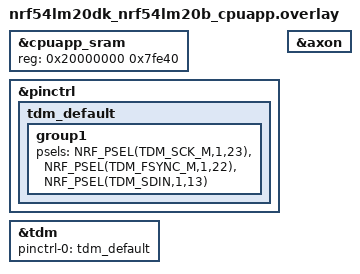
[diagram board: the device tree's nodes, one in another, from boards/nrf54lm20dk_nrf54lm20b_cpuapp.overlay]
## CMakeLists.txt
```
#
# Copyright (c) 2018 Nordic Semiconductor
#
# SPDX-License-Identifier: LicenseRef-Nordic-5-Clause
#
cmake_minimum_required(VERSION 3.20.0)

find_package(Zephyr REQUIRED HINTS $ENV{ZEPHYR_BASE})
project(NONE)

# NORDIC SDK APP START
target_sources(app PRIVATE
  src/main.c
  src/beamform.c
  src/bluetooth.c
  src/vad.c
  src/wakeword.c
  src/nrf_edgeai_generated/nrf_edgeai_user_model.c
)

# NORDIC SDK APP END
```

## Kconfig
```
#
# Copyright (c) 2018 Nordic Semiconductor
#
# SPDX-License-Identifier: LicenseRef-Nordic-5-Clause
#

source "Kconfig.zephyr"

menu "Wakeword and Keyword Spotting application"

config WW_PROBABILITY_THRESHOLD
	int "Wakeword probability threshold"
	range 0 1000
	default 700
	help
	   Probability threshold for wakeword detection model. The value is expressed in units of
	   1/1000.

config WW_HISTORY_SIZE
	int "Size of wakeword predictions history"
	range 1 32
	default 6
	help
	  Size of history of previous results from wakeword detection model.

config WW_COUNT_THRESHOLD
	int "Threshold for wakeword detection from predictions history"
	range 1 WW_HISTORY_SIZE
	default 4
	help
	  Number of predictions above threshold in predictions history required to confirm wakeword
	  detection.

endmenu

menu "Beamformer VAD / endpointing"

config APP_VAD_SAMPLE_RATE_HZ
	int "PCM sample rate handed to the VAD (Hz)"
	default 16000
	help
	  Must match the beamformer capture rate. Frame durations, and therefore
	  the silence and onset frame counts, are derived from this.

config APP_VAD_NOISE_INIT_RMS
	int "Initial noise-floor RMS estimate"
	default 25
	help
	  Seed value for the adaptive noise floor. Capture is always on, so the
	  floor is normally well converged before the Start button is pressed.
	  Matches the value proven in 10_beam_wakeword on the same int16 scale.

config APP_VAD_ONSET_RATIO_X8
	int "Speech-onset threshold as a multiple of the noise floor, in eighths"
	default 48
	help
	  threshold_on = noise_floor * this / 8. Default 48 is 6.0x. Measured
	  speech peaks on this hardware sit 13-19x above the room floor, so 6x
	  lands well inside speech while staying clear of the noise.

config APP_VAD_OFF_RATIO_X8
	int "Speech-continuation threshold as a multiple of the noise floor, in eighths"
	default 28
	help
	  threshold_off = noise_floor * this / 8. Default 20 is 2.5x. Must be
	  below APP_VAD_ONSET_RATIO_X8; the gap between them is the hysteresis
	  that carries the recording through pauses between words.

config APP_VAD_MARGIN_ON
	int "Absolute floor under the onset threshold (RMS counts)"
	default 40
	help
	  threshold_on never drops below noise_floor + this, so a near-silent
	  room cannot collapse the onset gate onto the noise.

config APP_VAD_MARGIN_OFF
	int "Absolute floor under the continuation threshold (RMS counts)"
	default 20
	help
	  threshold_off never drops below noise_floor + this. Must be less than
	  APP_VAD_MARGIN_ON.

config APP_VAD_ONSET_MS
	int "Sustained loud audio required to declare speech onset (ms)"
	default 32
	help
	  Debounces clicks, knocks and door slams. Rounded up to whole audio
	  frames, so on a 16 ms frame this is two frames.

config APP_VAD_SILENCE_END_MS
	int "Continuous silence that ends an utterance (ms)"
	default 600
	help
	  The endpoint pause. Ordinary gaps between words are shorter than this
	  and do not stop the recording. 500-1000 is the useful range: shorter
	  clips people who pause mid-sentence, longer adds latency.

config APP_VAD_MIN_SPEECH_MS
	int "Minimum utterance length before an endpoint may fire (ms)"
	default 300
	help
	  Guards against a single spurious onset frame immediately endpointing
	  and producing a near-empty recording.

config APP_VAD_NOISE_ALPHA_SHIFT
	int "Noise-floor adaptation shift"
	default 5
	help
	  noise += (rms - noise) >> this. Larger adapts more slowly.
	  5 gives a 1/32 step. The floor only adapts outside speech.

config APP_PREROLL_MS
	int "Audio kept from before the trigger (ms)"
	default 320
	help
	  A ring buffer of recent frames is always running, and its contents are
	  sent ahead of the live stream when recording starts. This covers the
	  wake-word model's confirmation delay, so the opening of an utterance
	  is not lost.

config APP_VAD_DEBUG
	bool "Verbose per-frame VAD telemetry"
	default y
	help
	  Logs rate-limited frame geometry, RMS, noise floor, both thresholds
	  and the silence/speech frame counters. Enough to see whether audio is
	  still arriving after you stop talking and whether the silence run is
	  reaching its target. Turn off for quiet production logs.

endmenu

menu "Nordic UART BLE GATT service sample"

config BT_NUS_THREAD_STACK_SIZE
	int "Thread stack size"
	default 1024
	help
	  Stack size used in each of the two threads

config BT_NUS_UART_BUFFER_SIZE
	int "UART payload buffer element size"
	default 40
	help
	  Size of the payload buffer in each RX and TX FIFO element

config BT_NUS_SECURITY_ENABLED
	bool "Security"
	default y
	select BT_SMP
	help
	  Enable Bluetooth LE security for the UART service

config BT_NUS_UART_RX_WAIT_TIME
	int "Timeout for UART RX complete event"
	default 50000
	help
	  Wait for RX complete event time in microseconds

config SETTINGS
	default y

config ZMS
	default y if (SOC_FLASH_NRF_RRAM || SOC_FLASH_NRF_MRAM)

config NVS
	default y if !(SOC_FLASH_NRF_RRAM || SOC_FLASH_NRF_MRAM)

endmenu
```

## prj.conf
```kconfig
# i2s
CONFIG_I2S=y

# serial console logs
CONFIG_LOG=y
CONFIG_LOG_DEFAULT_LEVEL=3
CONFIG_SERIAL=y
CONFIG_CONSOLE=y
CONFIG_UART_CONSOLE=y

# thread stakcs
CONFIG_MAIN_STACK_SIZE=4096
CONFIG_SYSTEM_WORKQUEUE_STACK_SIZE=2048
CONFIG_HEAP_MEM_POOL_SIZE=0

# buttons
CONFIG_GPIO=y
CONFIG_DK_LIBRARY=y

# bluetooth
CONFIG_BT=y
CONFIG_BT_PERIPHERAL=y
CONFIG_BT_NUS=y
CONFIG_BT_DEVICE_NAME="Beamformer"
CONFIG_BT_MAX_CONN=1
CONFIG_BT_L2CAP_TX_MTU=247
CONFIG_BT_BUF_ACL_TX_SIZE=251
CONFIG_BT_BUF_ACL_TX_COUNT=4
CONFIG_BT_BUF_ACL_RX_SIZE=251

# nRF Edge AI wakeword
CONFIG_NRF_EDGEAI=y
CONFIG_NRF_AXON=y
CONFIG_NEWLIB_LIBC=y
CONFIG_FPU=y
CONFIG_NRF_AXON_INTERLAYER_BUFFER_SIZE=7000
CONFIG_NRF_AXON_PSUM_BUFFER_SIZE=0

CONFIG_WW_PROBABILITY_THRESHOLD=700
CONFIG_WW_HISTORY_SIZE=6
CONFIG_WW_COUNT_THRESHOLD=4

CONFIG_NRF_SYS_EVENT=y
# VAD endpoint tuning
CONFIG_APP_VAD_SILENCE_END_MS=600
```

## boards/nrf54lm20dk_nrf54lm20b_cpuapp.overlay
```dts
/*
 * Copyright (c) 2026 Nordic Semiconductor ASA
 *
 * SPDX-License-Identifier: LicenseRef-Nordic-5-Clause
 */

 #include <dt-bindings/pinctrl/nrf-pinctrl.h>

&cpuapp_sram {
	reg = <0x20000000 0x7fe40>;
	ranges = <0x0 0x20000000 0x7fe40>;
};

&pinctrl {
	tdm_default: tdm_default {
		group1 {
			psels = <NRF_PSEL(TDM_SCK_M,1,23)>,
				<NRF_PSEL(TDM_FSYNC_M,1,22)>,
				<NRF_PSEL(TDM_SDIN,1,13)>;
		};
	};
};

&tdm {
	status = "okay";
	pinctrl-0 = <&tdm_default>;
	pinctrl-names = "default";
};

&axon {
	status = "okay";
};
```

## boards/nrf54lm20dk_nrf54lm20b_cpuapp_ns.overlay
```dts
/*
 * Copyright (c) 2026 N›ordic Semiconductor ASA
 *
 * SPDX-License-Identifier: LicenseRef-Nordic-5-Clause
 */

 #include <dt-bindings/pinctrl/nrf-pinctrl.h>

&cpuapp_sram {
	reg = <0x20000000 0x7fe40>;
	ranges = <0x0 0x20000000 0x7fe40>;
};

&pinctrl {
	tdm_default: tdm_default {
		group1 {
			psels = <NRF_PSEL(TDM_SCK_M,1,23)>,
				<NRF_PSEL(TDM_FSYNC_M,1,22)>,
				<NRF_PSEL(TDM_SDIN,1,13)>;
		};
	};
};

&tdm {
	status = "okay";
	pinctrl-0 = <&tdm_default>;
	pinctrl-names = "default";
};

&axon {
	status = "okay";
};
```

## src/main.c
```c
#include <errno.h>
#include <zephyr/kernel.h>
#include <zephyr/logging/log.h>
#include <zephyr/sys/atomic.h>
#include <zephyr/sys/util.h>
#include <string.h>
#include <dk_buttons_and_leds.h>

#include "beamform.h"
#include "bluetooth.h"
#include "vad.h"
#include "wakeword.h"

LOG_MODULE_REGISTER(main, LOG_LEVEL_INF);

#define MAX_STREAM_MS 30000U // never stopped speaking
#define NO_SPEECH_TIMEOUT_MS 10000U // never starts speaking
#define VAD_DEBUG_FRAMES_LISTENING 16U
#define VAD_DEBUG_FRAMES_IDLE 128U

enum audio_state {
	STATE_IDLE = BIT(0),
	STATE_LISTENING = BIT(1),
	STATE_FINALIZE = BIT(2),
	STATE_PROCESSING = BIT(3),
	STATE_RESPONDING = BIT(4),
};

enum stop_reason {
	STOP_NONE = 0,
	STOP_VAD_ENDPOINT,
	STOP_BUTTON,
	STOP_MAX_DURATION,
	STOP_NO_SPEECH,
};

enum start_reason {
	START_BUTTON = 0,
	START_WAKEWORD,
};

static const char *const start_reason_name[] = {
	[START_BUTTON] = "BTN1",
	[START_WAKEWORD] = "wake word",
};

static const char *const stop_reason_name[] = {
	[STOP_NONE] = "none",
	[STOP_VAD_ENDPOINT] = "VAD_ENDPOINT (automatic)",
	[STOP_BUTTON] = "BTN2 (manual failsafe)",
	[STOP_MAX_DURATION] = "max duration",
	[STOP_NO_SPEECH] = "no speech detected",
};

static atomic_t audio_state = ATOMIC_INIT(STATE_IDLE);
static atomic_t capture_enabled = ATOMIC_INIT(0);
static atomic_t last_stop_reason = ATOMIC_INIT(STOP_NONE);

/* Written by the capture thread, read by the main loop. */
static atomic_t speech_started = ATOMIC_INIT(0);
static atomic_t wakeword_ready = ATOMIC_INIT(0);
static atomic_t last_start_reason = ATOMIC_INIT(START_BUTTON);

static int64_t listening_start_ms;
static int64_t speech_start_ms;

/*
 * Preroll ring. Every frame captured while idle is kept here, and the whole
 * ring is flushed ahead of the live stream when a session opens. That covers
 * the wake-word model's confirmation delay, which would otherwise swallow the
 * first syllables of the command. Only the capture thread touches it: writes
 * happen while idle, and the flush is done by the capture thread on its first
 * recording frame rather than by whichever thread pressed the button.
 */
#define PREROLL_FRAMES ((CONFIG_APP_PREROLL_MS * 16000U) / (256U * 1000U))

#if PREROLL_FRAMES > 0
static int16_t preroll[PREROLL_FRAMES][256];
static uint32_t preroll_head;
static uint32_t preroll_used;
#endif
static atomic_t preroll_pending = ATOMIC_INIT(0);

static void preroll_store(const int16_t *samples, size_t count)
{
#if PREROLL_FRAMES > 0
	if (count != 256U) {
		return;
	}

	memcpy(preroll[preroll_head], samples, count * sizeof(int16_t));
	preroll_head = (preroll_head + 1U) % PREROLL_FRAMES;
	if (preroll_used < PREROLL_FRAMES) {
		preroll_used++;
	}
#else
	ARG_UNUSED(samples);
	ARG_UNUSED(count);
#endif
}

static void preroll_flush(void)
{
#if PREROLL_FRAMES > 0
	uint32_t start = (preroll_head + PREROLL_FRAMES - preroll_used) % PREROLL_FRAMES;
	uint32_t sent = 0U;

	for (uint32_t i = 0; i < preroll_used; i++) {
		uint32_t idx = (start + i) % PREROLL_FRAMES;

		if (bluetooth_enqueue_audio(preroll[idx], 256U) == 0) {
			sent++;
		}
	}

	LOG_INF("Preroll: sent %u of %u frames (%u ms)", sent, preroll_used,
		sent * 256U * 1000U / 16000U);
	preroll_used = 0U;
#endif
}

static const struct vad_config vad_config = {
	.sample_rate_hz = CONFIG_APP_VAD_SAMPLE_RATE_HZ,
	.noise_init_rms = CONFIG_APP_VAD_NOISE_INIT_RMS,
	.onset_ratio_x8 = CONFIG_APP_VAD_ONSET_RATIO_X8,
	.off_ratio_x8 = CONFIG_APP_VAD_OFF_RATIO_X8,
	.margin_on = CONFIG_APP_VAD_MARGIN_ON,
	.margin_off = CONFIG_APP_VAD_MARGIN_OFF,
	.onset_ms = CONFIG_APP_VAD_ONSET_MS,
	.silence_end_ms = CONFIG_APP_VAD_SILENCE_END_MS,
	.min_speech_ms = CONFIG_APP_VAD_MIN_SPEECH_MS,
	.noise_alpha_shift = CONFIG_APP_VAD_NOISE_ALPHA_SHIFT,
};

static void log_vad_telemetry(const char *tag, bool listening)
{
	struct vad_debug d;

	vad_get_debug(&d);

	LOG_INF("VAD[%s] frame=%u smp/%u B (%u ms @%u Hz, 1 ch) rms=%u noise=%u "
		"on=%u off=%u -> %s | speech_active=%d onset=%u/%u silence=%u/%u "
		"speech=%u/%u latched=%d listening=%d",
		tag, d.frame_samples, d.frame_bytes, d.frame_ms, d.sample_rate_hz,
		d.rms, d.noise_rms, d.threshold_on, d.threshold_off,
		d.frame_is_speech ? "SPEECH" : "silence",
		d.speech_active ? 1 : 0, d.onset_frames, d.onset_frames_req,
		d.silence_frames, d.silence_end_frames,
		d.speech_frames, d.min_speech_frames, d.endpoint_latched ? 1 : 0,
		listening ? 1 : 0);
}

static void enter_state(enum audio_state next_state);

static bool request_finalize(enum stop_reason reason)
{
	if (!atomic_cas(&audio_state, STATE_LISTENING, STATE_FINALIZE)) {
		return false;
	}

	atomic_clear(&capture_enabled);
	atomic_set(&last_stop_reason, reason);

	LOG_INF("Recording stop: %s (after %lld ms)", stop_reason_name[reason],
		k_uptime_get() - listening_start_ms);
	LOG_INF("STATE_FINALIZE: capture disabled, draining BLE TX queue");

	return true;
}

static bool request_listen(enum start_reason reason)
{
	if (!atomic_cas(&audio_state, STATE_IDLE, STATE_LISTENING)) {
		return false;
	}

	atomic_set(&last_start_reason, reason);
	enter_state(STATE_LISTENING);

	return true;
}

static void enter_state(enum audio_state next_state)
{
	atomic_set(&audio_state, next_state);

	switch (next_state) {
	case STATE_IDLE:
		atomic_clear(&capture_enabled);
		ww_reset();
		LOG_INF("STATE_IDLE: say the wake word or press BTN1");
		break;

	case STATE_LISTENING:
		vad_reset_endpoint();
		ww_reset();
		bluetooth_tx_reset_stats();
		atomic_set(&preroll_pending, 1);
		atomic_clear(&speech_started);
		atomic_set(&last_stop_reason, STOP_NONE);
		listening_start_ms = k_uptime_get();
		speech_start_ms = 0;
		atomic_set(&capture_enabled, 1);
		LOG_INF("STATE_LISTENING: started by %s, waiting for speech, "
			"streaming enabled",
			start_reason_name[atomic_get(&last_start_reason)]);
		break;

	case STATE_FINALIZE:
		atomic_clear(&capture_enabled);
		LOG_INF("STATE_FINALIZE: capture disabled, draining BLE TX queue");
		break;

	case STATE_PROCESSING:
		atomic_clear(&capture_enabled);
		LOG_INF("STATE_PROCESSING");
		break;

	case STATE_RESPONDING:
		atomic_clear(&capture_enabled);
		LOG_INF("STATE_RESPONDING");
		break;

	default:
		LOG_ERR("Invalid state: 0x%x", next_state);
		atomic_set(&audio_state, STATE_IDLE);
		atomic_clear(&capture_enabled);
		break;
	}
}

static void on_beamformed_chunk(const int16_t *samples, size_t count)
{
	static uint32_t frames_since_log;
	enum audio_state current;
	enum vad_event event;
	bool listening;
	int err;

	current = (enum audio_state)atomic_get(&audio_state);
	listening = (current == STATE_LISTENING) && atomic_get(&capture_enabled);

	event = vad_process(samples, count, listening);

	if (!listening && current == STATE_IDLE && atomic_get(&wakeword_ready)) {
		bool ww_detected = false;

		err = ww_process(samples, (uint16_t)count, &ww_detected);
		if (err && err != -EBUSY) {
			LOG_WRN("Wakeword inference failed: %d", err);
		} else if (ww_detected) {
			LOG_INF("Wake word detected");
			request_listen(START_WAKEWORD);
			return;
		}
	}

	if (IS_ENABLED(CONFIG_APP_VAD_DEBUG)) {
		uint32_t period = listening ? VAD_DEBUG_FRAMES_LISTENING
					    : VAD_DEBUG_FRAMES_IDLE;

		if (++frames_since_log >= period) {
			frames_since_log = 0U;
			log_vad_telemetry(listening ? "rec" : "idle", listening);
		}
	}

	if (!listening) {
		preroll_store(samples, count);
		return;
	}

	if (atomic_cas(&preroll_pending, 1, 0)) {
		preroll_flush();
	}

	switch (event) {
	case VAD_SPEECH_STARTED:
		atomic_set(&speech_started, 1);
		speech_start_ms = k_uptime_get();
		LOG_INF("Speech onset detected (%lld ms after start)",
			speech_start_ms - listening_start_ms);
		if (IS_ENABLED(CONFIG_APP_VAD_DEBUG)) {
			log_vad_telemetry("onset", true);
		}
		break;

	case VAD_ENDPOINT:
		LOG_INF("VAD endpoint: %u ms of continuous silence after speech",
			CONFIG_APP_VAD_SILENCE_END_MS);
		if (IS_ENABLED(CONFIG_APP_VAD_DEBUG)) {
			log_vad_telemetry("endpoint", true);
		}
		
		(void)bluetooth_enqueue_audio(samples, count);
		request_finalize(STOP_VAD_ENDPOINT);
		return;

	case VAD_NO_EVENT:
	default:
		break;
	}

	err = bluetooth_enqueue_audio(samples, count);
	if (err && err != -ENOTCONN) {
		LOG_WRN("BLE TX queue rejected audio chunk: %d", err);
	}
}


// Button handler. BTN1 starts a session, BTN2 is the manual failsafe stop.
static void button_changed(uint32_t state, uint32_t changed)
{
	uint32_t pressed = state & changed;
	enum audio_state current = (enum audio_state)atomic_get(&audio_state);

	if (pressed & DK_BTN1_MSK) {
		if (request_listen(START_BUTTON)) {
			LOG_INF("BTN1 start requested");
		} else {
			LOG_WRN("BTN1 ignored: session already active (state 0x%x)",
				current);
		}
		return;
	}

	if (pressed & DK_BTN2_MSK) {
		if (!request_finalize(STOP_BUTTON)) {
			LOG_WRN("BTN2 ignored: not recording (state 0x%x)", current);
		}
	}
}

static void finalize_processing(void)
{
	enum audio_state current = (enum audio_state)atomic_get(&audio_state);
	uint32_t dropped;

	if (current == STATE_LISTENING) {
		int64_t elapsed = k_uptime_get() - listening_start_ms;

		if (elapsed >= MAX_STREAM_MS) {
			LOG_WRN("Maximum stream duration reached");
			request_finalize(STOP_MAX_DURATION);
		} else if (!atomic_get(&speech_started) &&
			   elapsed >= NO_SPEECH_TIMEOUT_MS) {
			LOG_WRN("No speech within %u ms", NO_SPEECH_TIMEOUT_MS);
			request_finalize(STOP_NO_SPEECH);
		}
		return;
	}

	if (current != STATE_FINALIZE || !bluetooth_tx_drained()) {
		return;
	}

	dropped = bluetooth_tx_dropped_chunks();
	if (dropped) {
		LOG_WRN("Finalization: %u audio chunks were dropped; "
			"the received recording has gaps", dropped);
	}

	LOG_INF("Finalization complete: reason=%s, %lld ms captured, "
		"speech_detected=%d",
		stop_reason_name[atomic_get(&last_stop_reason)],
		k_uptime_get() - listening_start_ms,
		atomic_get(&speech_started) ? 1 : 0);

	// post recording
	enter_state(STATE_PROCESSING);
	enter_state(STATE_IDLE);
}

int main(void)
{
	int err = dk_leds_init();

	if (err) {
		return err;
	}

	err = dk_buttons_init(button_changed);
	if (err) {
		return err;
	}

	err = vad_init(&vad_config);
	if (err) {
		LOG_ERR("VAD initialization failed: %d", err);
		return err;
	}

	err = ww_init();
	if (err) {
		LOG_ERR("Wakeword initialization failed: %d", err);
		return err;
	}
	atomic_set(&wakeword_ready, 1);

	err = bluetooth_init();
	if (err) {
		LOG_ERR("Bluetooth initialization failed: %d", err);
		return err;
	}

	err = beamform_init(on_beamformed_chunk);
	if (err) {
		LOG_ERR("Beamformer initialization failed: %d", err);
		return err;
	}

	err = beamform_start();
	if (err) {
		LOG_ERR("Always-on beamforming failed to start: %d", err);
		return err;
	}

	LOG_INF("Beamforming + wake word + adaptive VAD active");
	LOG_INF("VAD: %u Hz, endpoint after %u ms silence, min utterance %u ms",
		(uint32_t)CONFIG_APP_VAD_SAMPLE_RATE_HZ,
		(uint32_t)CONFIG_APP_VAD_SILENCE_END_MS,
		(uint32_t)CONFIG_APP_VAD_MIN_SPEECH_MS);
	LOG_INF("VAD thresholds: on=%u/8x off=%u/8x of noise floor "
		"(min +%u / +%u), noise init=%u, preroll %u frames",
		(uint32_t)CONFIG_APP_VAD_ONSET_RATIO_X8,
		(uint32_t)CONFIG_APP_VAD_OFF_RATIO_X8,
		(uint32_t)CONFIG_APP_VAD_MARGIN_ON,
		(uint32_t)CONFIG_APP_VAD_MARGIN_OFF,
		(uint32_t)CONFIG_APP_VAD_NOISE_INIT_RMS,
		(uint32_t)PREROLL_FRAMES);
	LOG_INF("Wakeword: prob>%u/1000, %u of last %u windows",
		(uint32_t)CONFIG_WW_PROBABILITY_THRESHOLD,
		(uint32_t)CONFIG_WW_COUNT_THRESHOLD,
		(uint32_t)CONFIG_WW_HISTORY_SIZE);
	LOG_INF("Wake word or BTN1: start recording   BTN2: manual failsafe stop");

	enter_state(STATE_IDLE);

	for (;;) {
		finalize_processing();
		k_sleep(K_MSEC(10));
	}
}
```

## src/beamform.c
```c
#include <errno.h>
#include <stdint.h>

#include <zephyr/device.h>
#include <zephyr/devicetree.h>
#include <zephyr/drivers/i2s.h>
#include <zephyr/kernel.h>
#include <zephyr/logging/log.h>
#include <zephyr/sys/atomic.h>
#include <zephyr/sys/util.h>

#include "beamform.h"

LOG_MODULE_REGISTER(beamform, LOG_LEVEL_INF);

#define SAMPLE_RATE       16000
#define SAMPLE_BIT_WIDTH  32
#define CHANNELS          2

#define BLOCK_PAIRS       256
#define BLOCK_BYTES       (BLOCK_PAIRS * CHANNELS * sizeof(int32_t))
#define BLOCK_COUNT       4
#define CAPTURE_GAIN_SHIFT 0

#define TDM_NODE DT_NODELABEL(tdm)

#if !DT_NODE_EXISTS(TDM_NODE)
#error "TDM node does not exist in the final devicetree"
#endif

#if !DT_NODE_HAS_STATUS(TDM_NODE, okay)
#error "TDM node is not enabled in the final devicetree"
#endif

K_MEM_SLAB_DEFINE_IN_SECT_STATIC(rx_slab, __nocache, BLOCK_BYTES, BLOCK_COUNT, 4);
K_THREAD_STACK_DEFINE(capture_stack, 4096);

static const struct device *const i2s = DEVICE_DT_GET(TDM_NODE);

static const struct i2s_config i2s_cfg = {
	.word_size = SAMPLE_BIT_WIDTH,
	.channels = CHANNELS,
	.format = I2S_FMT_DATA_FORMAT_I2S,
	/* The nRF TDM drives both clocks; the INMP441 is always a clock slave. */
	.options = I2S_OPT_BIT_CLK_MASTER | I2S_OPT_FRAME_CLK_MASTER,
	.frame_clk_freq = SAMPLE_RATE,
	.mem_slab = &rx_slab,
	.block_size = BLOCK_BYTES,
	.timeout = 2000,
};

static struct k_thread capture_thread_data;
static atomic_t beamforming_active = ATOMIC_INIT(0);
static void (*chunk_ready)(const int16_t *samples, size_t count);

/* Sign-preserving unpack of the 24-bit payload from its 32-bit I2S slot. */
static inline int32_t extract_sample_24(int32_t raw)
{
	return raw >> 8;
}

static inline int16_t saturate_int16(int32_t x)
{
	if (x > INT16_MAX) {
		return INT16_MAX;
	}
	if (x < INT16_MIN) {
		return INT16_MIN;
	}
	return (int16_t)x;
}

static void capture(void *a, void *b, void *c)
{
	ARG_UNUSED(a);
	ARG_UNUSED(b);
	ARG_UNUSED(c);

	int err = i2s_trigger(i2s, I2S_DIR_RX, I2S_TRIGGER_START);

	if (err) {
		LOG_ERR("I2S start failed: %d", err);
		atomic_clear(&beamforming_active);
		return;
	}

	LOG_INF("capture: %d Hz, %d ch, %d-bit slots, %u frames/block (%u ms)",
		SAMPLE_RATE, CHANNELS, SAMPLE_BIT_WIDTH, (unsigned int)BLOCK_PAIRS,
		(unsigned int)((1000U * BLOCK_PAIRS) / SAMPLE_RATE));

	while (atomic_get(&beamforming_active)) {
		void *block;
		size_t bytes;
		int16_t mono_chunk[BLOCK_PAIRS];

		err = i2s_read(i2s, &block, &bytes);
		if (err) {
			if (err != -EAGAIN) {
				LOG_WRN("I2S read failed: %d", err);
			}
			continue;
		}

		const int32_t *stereo = block;
		size_t pairs = bytes / (CHANNELS * sizeof(int32_t));

		pairs = MIN(pairs, (size_t)BLOCK_PAIRS);

		for (size_t i = 0; i < pairs; i++) {
			/*
			 * Broadside 2-mic beamformer, center steered:
			 *   y[n] = (L[n] + R[n]) / 2
			 * Summing in the 24-bit domain keeps the average exact
			 * and cannot overflow int32_t.
			 */
			int32_t left = extract_sample_24(stereo[CHANNELS * i]);
			int32_t right = extract_sample_24(stereo[CHANNELS * i + 1]);
			int32_t sum = (left + right) / 2;

			mono_chunk[i] = saturate_int16(sum >> (8 - CAPTURE_GAIN_SHIFT));
		}

		/*
		 * Hand the frame over before releasing the DMA block. The
		 * consumer copies synchronously, so mono_chunk staying on this
		 * stack is safe and no ownership is transferred.
		 */
		if (chunk_ready && pairs > 0U) {
			chunk_ready(mono_chunk, pairs);
		}

		k_mem_slab_free(&rx_slab, block);
	}

	i2s_trigger(i2s, I2S_DIR_RX, I2S_TRIGGER_DROP);
}

int beamform_init(void (*chunk_cb)(const int16_t *samples, size_t count))
{
	if (!device_is_ready(i2s)) {
		return -ENODEV;
	}

	chunk_ready = chunk_cb;
	return i2s_configure(i2s, I2S_DIR_RX, &i2s_cfg);
}

int beamform_start(void)
{
	if (!atomic_cas(&beamforming_active, 0, 1)) {
		return -EALREADY;
	}

	k_thread_create(&capture_thread_data, capture_stack,
			K_THREAD_STACK_SIZEOF(capture_stack), capture,
			NULL, NULL, NULL, 6, 0, K_NO_WAIT);
	k_thread_name_set(&capture_thread_data, "audio_capture");

	return 0;
}

uint32_t beamform_sample_rate_hz(void)
{
	return SAMPLE_RATE;
}

uint32_t beamform_frame_samples(void)
{
	return BLOCK_PAIRS;
}
```

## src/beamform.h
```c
#ifndef BEAMFORM_H_
#define BEAMFORM_H_

#include <stdbool.h>
#include <stddef.h>
#include <stdint.h>

/*
 * Always-on 2-microphone capture with a centre-steered broadside beamformer.
 * The registered callback runs on the dedicated capture thread (not an ISR)
 * and receives mono, little-endian, signed 16-bit PCM. `count` is a sample
 * count, not a byte count. The buffer is only valid for the duration of the
 * call.
 */
int beamform_init(void (*chunk_cb)(const int16_t *samples, size_t count));
int beamform_start(void);

uint32_t beamform_sample_rate_hz(void);
uint32_t beamform_frame_samples(void);

#endif
```

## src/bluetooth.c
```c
#include <errno.h>
#include <string.h>
#include <zephyr/bluetooth/bluetooth.h>
#include <zephyr/bluetooth/conn.h>
#include <zephyr/bluetooth/gatt.h>
#include <zephyr/kernel.h>
#include <zephyr/logging/log.h>
#include <zephyr/sys/atomic.h>
#include <bluetooth/services/nus.h>

#include "bluetooth.h"

LOG_MODULE_REGISTER(bluetooth, LOG_LEVEL_INF);

#define DEVICE_NAME CONFIG_BT_DEVICE_NAME
#define DEVICE_NAME_LEN (sizeof(DEVICE_NAME) - 1)

#define AUDIO_CHUNK_SAMPLES 256
/*
 * Deep enough to hold a full preroll burst plus live audio while the link
 * catches up. 8 chunks was only 128 ms, which the preroll flush alone would
 * overrun.
 */
#define AUDIO_QUEUE_DEPTH 32

struct audio_chunk {
    size_t samples;
    int16_t pcm[AUDIO_CHUNK_SAMPLES];
};

K_MSGQ_DEFINE(audio_tx_queue, sizeof(struct audio_chunk), AUDIO_QUEUE_DEPTH, 4);
K_THREAD_STACK_DEFINE(ble_tx_stack, 2048);

/* Longest a queued chunk waits for the link to come back before it is dropped.
 * Bounded so STATE_FINALIZE can always drain and return the app to idle, even
 * if the central disconnects mid-utterance. */
#define TX_LINK_WAIT_MS 500

static struct bt_conn *connection;
static atomic_t subscribed = ATOMIC_INIT(0);
/*
 * Chunks accepted by bluetooth_enqueue_audio() but not yet fully sent. This
 * counts the one being transmitted as well as those still in the queue, so
 * bluetooth_tx_drained() has no window where an in-flight chunk looks idle.
 */
static atomic_t tx_pending = ATOMIC_INIT(0);
static atomic_t tx_dropped = ATOMIC_INIT(0);
static struct k_thread ble_tx_thread_data;

static const struct bt_data ad[] = {
    BT_DATA_BYTES(BT_DATA_FLAGS, BT_LE_AD_GENERAL | BT_LE_AD_NO_BREDR),
    BT_DATA(BT_DATA_NAME_COMPLETE, DEVICE_NAME, DEVICE_NAME_LEN),
};
static const struct bt_data sd[] = {
    BT_DATA_BYTES(BT_DATA_UUID128_ALL, BT_UUID_NUS_VAL),
};

static bool bluetooth_ready(void) {
    return connection != NULL && atomic_get(&subscribed);
}

static void connected(struct bt_conn *conn, uint8_t err) {
    if(err) {
        LOG_WRN("BLE connection failed: %u", err);
        return;
    }

    connection = bt_conn_ref(conn);
    LOG_INF("BLE connected");
}

static void disconnected(struct bt_conn *conn, uint8_t reason) {
    ARG_UNUSED(conn);
    ARG_UNUSED(reason);

    atomic_clear(&subscribed);

    if(connection) {
        bt_conn_unref(connection);
        connection = NULL;
    }

    LOG_INF("BLE disconnected");
    bt_le_adv_start(BT_LE_ADV_CONN_FAST_2, ad, ARRAY_SIZE(ad), sd, 
        ARRAY_SIZE(sd));
}

BT_CONN_CB_DEFINE(conn_callbacks) = {
    .connected = connected,
    .disconnected = disconnected,
};

static void nus_send_enabled(enum bt_nus_send_status status) {
    atomic_set(&subscribed, status == BT_NUS_SEND_STATUS_ENABLED);
    LOG_INF("NUS notifications %s", atomic_get(&subscribed) ? "enabled" : "disabled");
}

static struct bt_nus_cb nus_cb = {
    .send_enabled = nus_send_enabled,
};

static int send_chunk(const struct audio_chunk *chunk) {
    if (!bluetooth_ready()) {
        return -ENOTCONN;
    }

    uint16_t mtu = bt_gatt_get_mtu(connection);
    size_t samples_per_packet = MAX((size_t)1, (mtu-3) / sizeof(int16_t));

    for(size_t offset = 0; offset < chunk->samples; offset += samples_per_packet) {
        size_t count = MIN(samples_per_packet, chunk->samples - offset);
        int err = bt_nus_send(NULL, (const uint8_t *)&chunk->pcm[offset], count*sizeof(int16_t));

        if(err) return err;

        k_sleep(K_MSEC(1));
    }

    return 0;
}


static void ble_tx_worker(void *a, void *b, void *c) {
    ARG_UNUSED(a);
    ARG_UNUSED(b);
    ARG_UNUSED(c);

    while(true) {
        struct audio_chunk chunk;
        int err = k_msgq_get(&audio_tx_queue, &chunk, K_FOREVER);
        if (err) continue;

        for (int waited = 0; !bluetooth_ready() && waited < TX_LINK_WAIT_MS; waited += 20) {
            k_sleep(K_MSEC(20));
        }

        if (bluetooth_ready()) {
            err = send_chunk(&chunk);
            if (err) {
                atomic_inc(&tx_dropped);
                LOG_WRN("BLE send failed; dropped one chunk: %d", err);
            }
        } else {
            atomic_inc(&tx_dropped);
            LOG_WRN("BLE link down; dropped one chunk");
        }

        atomic_dec(&tx_pending);
    }
}

int bluetooth_init(void) {
    int err = bt_enable(NULL);
    if(err) {
        return err;
    }

    err = bt_nus_init(&nus_cb);
    if(err) {
        return err;
    }

    k_thread_create(&ble_tx_thread_data, ble_tx_stack, 
        K_THREAD_STACK_SIZEOF(ble_tx_stack), ble_tx_worker,
        NULL, NULL, NULL, 7, 0, K_NO_WAIT);

    return bt_le_adv_start(BT_LE_ADV_CONN_FAST_2, ad, ARRAY_SIZE(ad), 
        sd, ARRAY_SIZE(sd));
}

int bluetooth_enqueue_audio(const int16_t *samples, size_t count) {
    if(count==0 || count > AUDIO_CHUNK_SAMPLES) {
        return -EINVAL;
    }

    if(!bluetooth_ready()) {
        return -ENOTCONN;
    }

    struct audio_chunk chunk = {
        .samples = count,
    };

    memcpy(chunk.pcm, samples, count*sizeof(int16_t));

    /*
     * Claim the slot before the put so the counter can never lag behind the
     * queue. Released by the TX worker once the chunk has actually been sent.
     */
    atomic_inc(&tx_pending);

    int err = k_msgq_put(&audio_tx_queue, &chunk, K_NO_WAIT);

    if (err) {
        atomic_dec(&tx_pending);
        /* Queue full: the link is not keeping up and this frame is lost,
         * which is audible as a gap. Surface it rather than hiding it. */
        atomic_inc(&tx_dropped);
    }

    return err;
}

bool bluetooth_tx_drained(void) {
    return atomic_get(&tx_pending) == 0;
}

uint32_t bluetooth_tx_dropped_chunks(void) {
    return (uint32_t)atomic_get(&tx_dropped);
}

void bluetooth_tx_reset_stats(void) {
    atomic_clear(&tx_dropped);
}
```

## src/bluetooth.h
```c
#ifndef BLUETOOTH_H_
#define BLUETOOTH_H_

#include <stdbool.h>
#include <stddef.h>
#include <stdint.h>

int bluetooth_init(void);
int bluetooth_enqueue_audio(const int16_t *samples, size_t count);
bool bluetooth_tx_drained(void);

/* Chunks lost since the last bluetooth_tx_reset_stats(), either because the
 * TX queue was full or because the link was down. Any non-zero value means
 * the received audio has gaps. */
uint32_t bluetooth_tx_dropped_chunks(void);
void bluetooth_tx_reset_stats(void);

#endif
```

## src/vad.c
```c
#include <errno.h>
#include <limits.h>

#include <zephyr/kernel.h>
#include <zephyr/sys/util.h>

#include "vad.h"

struct vad_state {
	struct vad_config config;

	uint32_t noise_rms;
	uint32_t rms;

	uint32_t frame_samples;
	uint32_t frame_ms;
	uint32_t silence_end_frames;
	uint32_t min_speech_frames;
	uint32_t onset_frames_req;

	uint32_t silence_frames;
	uint32_t speech_frames;
	uint32_t onset_frames;

	bool frame_is_speech;
	bool speech_active;
	bool endpoint_latched;
	bool initialized;
};

static struct vad_state state;

static uint32_t isqrt64(uint64_t x)
{
	uint64_t op = x;
	uint64_t res = 0;
	uint64_t one = 1ULL << 62;

	while (one > op) {
		one >>= 2;
	}

	while (one != 0U) {
		if (op >= (res + one)) {
			op -= res + one;
			res = (res >> 1) + one;
		} else {
			res >>= 1;
		}
		one >>= 2;
	}

	return (uint32_t)res;
}

/*
 * RMS of one mono int16 frame. Worst-case energy per sample is 2^30, so the
 * 64-bit accumulator cannot overflow for any realistic frame length.
 */
static uint32_t rms_i16(const int16_t *samples, size_t count)
{
	uint64_t energy = 0;

	for (size_t i = 0; i < count; i++) {
		int32_t sample = samples[i];

		energy += (uint64_t)((int64_t)sample * sample);
	}

	return isqrt64(energy / (uint64_t)count);
}

static uint32_t threshold_on(void)
{
	uint32_t scaled = (state.noise_rms * state.config.onset_ratio_x8) / 8U;

	return MAX(scaled, state.noise_rms + state.config.margin_on);
}

static uint32_t threshold_off(void)
{
	uint32_t scaled = (state.noise_rms * state.config.off_ratio_x8) / 8U;

	return MAX(scaled, state.noise_rms + state.config.margin_off);
}

/*
 * Adapt the noise floor towards the current frame, and only from frames that
 * are clearly not speech. Never called once an utterance is in progress, so
 * the floor cannot chase speech energy and cannot drift during the very pause
 * being measured.
 */
static void update_noise_floor(uint32_t rms)
{
	int32_t noise = (int32_t)state.noise_rms;
	int32_t error = (int32_t)rms - noise;
	int32_t step;

	/*
	 * Learn only from frames that are clearly not speech, meaning anything
	 * under the onset gate. Gating on the lower off-threshold instead is a
	 * ratchet: once the floor sinks beneath the ambient level no frame ever
	 * qualifies again, and the floor is stuck there for good.
	 */
	if (rms >= threshold_on()) {
		return;
	}

	if (error < 0) {
		/* Drop quickly onto quiet moments so the floor hugs the minima. */
		step = error >> 2;
	} else {
		/*
		 * Rise slowly, but always by at least one count. A pure shift
		 * truncates small errors to zero, which is the other way the
		 * floor freezes in place.
		 */
		step = MAX(1, error >> state.config.noise_alpha_shift);
	}

	state.noise_rms = (uint32_t)MAX(noise + step, 1);
}

/* Derive frame counts from the real frame length rather than assuming one. */
static void update_frame_timing(size_t count)
{
	if (state.frame_samples == (uint32_t)count) {
		return;
	}

	state.frame_samples = (uint32_t)count;
	state.frame_ms = MAX(1U, (uint32_t)((1000ULL * count) / state.config.sample_rate_hz));

	state.silence_end_frames =
		MAX(1U, (state.config.silence_end_ms + state.frame_ms - 1U) / state.frame_ms);
	state.min_speech_frames =
		(state.config.min_speech_ms + state.frame_ms - 1U) / state.frame_ms;
	state.onset_frames_req =
		MAX(1U, (state.config.onset_ms + state.frame_ms - 1U) / state.frame_ms);
}

int vad_init(const struct vad_config *config)
{
	if (config == NULL || config->sample_rate_hz == 0U ||
	    config->silence_end_ms == 0U || config->noise_alpha_shift == 0U ||
	    config->noise_alpha_shift >= 31U) {
		return -EINVAL;
	}

	/* Hysteresis only means anything if the onset gate sits above the off gate. */
	if (config->margin_on <= config->margin_off ||
	    config->onset_ratio_x8 <= config->off_ratio_x8 ||
	    config->off_ratio_x8 <= 8U) {
		return -EINVAL;
	}

	state.config = *config;
	state.noise_rms = MAX(1U, config->noise_init_rms);
	state.rms = 0U;

	state.frame_samples = 0U;
	state.frame_ms = 1U;
	state.silence_end_frames = 1U;
	state.min_speech_frames = 0U;
	state.onset_frames_req = 1U;

	state.silence_frames = 0U;
	state.speech_frames = 0U;
	state.onset_frames = 0U;
	state.frame_is_speech = false;
	state.speech_active = false;
	state.endpoint_latched = false;
	state.initialized = true;

	return 0;
}

void vad_reset_endpoint(void)
{
	state.silence_frames = 0U;
	state.speech_frames = 0U;
	state.onset_frames = 0U;
	state.frame_is_speech = false;
	state.speech_active = false;
	state.endpoint_latched = false;
}

void vad_reset_all(void)
{
	state.noise_rms = MAX(1U, state.config.noise_init_rms);
	state.rms = 0U;
	vad_reset_endpoint();
}

enum vad_event vad_process(const int16_t *samples, size_t count, bool endpoint_tracking)
{
	if (!state.initialized || samples == NULL || count == 0U) {
		return VAD_NO_EVENT;
	}

	update_frame_timing(count);
	state.rms = rms_i16(samples, count);
	state.frame_is_speech = (state.rms >= threshold_off());

	/*
	 * Idle. Learn the room and hold the utterance counters clear, so a
	 * well-converged noise floor is ready the moment recording starts.
	 */
	if (!endpoint_tracking) {
		update_noise_floor(state.rms);
		state.silence_frames = 0U;
		state.speech_frames = 0U;
		state.onset_frames = 0U;
		state.speech_active = false;
		state.endpoint_latched = false;
		return VAD_NO_EVENT;
	}

	/*
	 * Waiting for speech. Quiet frames here mean the talker has not begun,
	 * not that the utterance has ended, so they must never count towards
	 * the endpoint. This is what stops a session ending before it starts.
	 */
	if (!state.speech_active) {
		if (state.rms > threshold_on()) {
			state.onset_frames++;

			if (state.onset_frames >= state.onset_frames_req) {
				state.speech_active = true;
				state.silence_frames = 0U;
				state.speech_frames = state.onset_frames;
				state.onset_frames = 0U;
				return VAD_SPEECH_STARTED;
			}

			state.silence_frames = 0U;
			return VAD_NO_EVENT;
		}

		state.onset_frames = 0U;
		update_noise_floor(state.rms);
		state.silence_frames = 0U;
		return VAD_NO_EVENT;
	}

	/*
	 * Recording speech. The noise floor stays frozen from here until the
	 * next vad_reset_endpoint(): if it kept adapting during the trailing
	 * pause, threshold_off() would sink under the room noise and the
	 * silence run would keep restarting, so the utterance would never end.
	 */
	state.speech_frames++;

	if (state.frame_is_speech) {
		/* An ordinary pause between words ends here; the run restarts. */
		state.silence_frames = 0U;
		return VAD_NO_EVENT;
	}

	state.silence_frames++;

	if (state.endpoint_latched) {
		return VAD_NO_EVENT;
	}

	if (state.silence_frames >= state.silence_end_frames &&
	    state.speech_frames >= state.min_speech_frames) {
		state.endpoint_latched = true;
		return VAD_ENDPOINT;
	}

	return VAD_NO_EVENT;
}

bool vad_speech_active(void)
{
	return state.speech_active;
}

void vad_get_debug(struct vad_debug *debug)
{
	if (debug == NULL) {
		return;
	}

	debug->rms = state.rms;
	debug->noise_rms = state.noise_rms;
	debug->threshold_on = threshold_on();
	debug->threshold_off = threshold_off();
	debug->silence_frames = state.silence_frames;
	debug->silence_end_frames = state.silence_end_frames;
	debug->speech_frames = state.speech_frames;
	debug->min_speech_frames = state.min_speech_frames;
	debug->onset_frames = state.onset_frames;
	debug->onset_frames_req = state.onset_frames_req;
	debug->frame_samples = state.frame_samples;
	debug->frame_bytes = state.frame_samples * (uint32_t)sizeof(int16_t);
	debug->frame_ms = state.frame_ms;
	debug->sample_rate_hz = state.config.sample_rate_hz;
	debug->speech_active = state.speech_active;
	debug->frame_is_speech = state.frame_is_speech;
	debug->endpoint_latched = state.endpoint_latched;
}
```

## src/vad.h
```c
#ifndef VAD_H
#define VAD_H

#include <stdbool.h>
#include <stddef.h>
#include <stdint.h>

struct vad_config {
	uint32_t sample_rate_hz;
	uint32_t noise_init_rms;

	/*
	 * Thresholds scale with the tracked noise floor, expressed in eighths:
	 *   threshold = noise * ratio_x8 / 8
	 * Speech-to-noise ratio holds far steadier across rooms than any fixed
	 * margin does, so this keeps the decision boundary at the same relative
	 * point whether the room is quiet or noisy.
	 */
	uint32_t onset_ratio_x8;
	uint32_t off_ratio_x8;

	/*
	 * Absolute floors beneath those ratios, so a near-silent room cannot
	 * collapse the thresholds down onto the noise itself.
	 *   threshold_on  = MAX(noise * onset_ratio_x8 / 8, noise + margin_on)
	 *   threshold_off = MAX(noise * off_ratio_x8   / 8, noise + margin_off)
	 */
	uint32_t margin_on;
	uint32_t margin_off;

	uint32_t onset_ms;
	uint32_t silence_end_ms;
	uint32_t min_speech_ms;
	uint8_t noise_alpha_shift;
};

struct vad_debug {
	uint32_t rms;
	uint32_t noise_rms;
	uint32_t threshold_on;
	uint32_t threshold_off;
	uint32_t silence_frames;
	uint32_t silence_end_frames;
	uint32_t speech_frames;
	uint32_t min_speech_frames;
	uint32_t onset_frames;
	uint32_t onset_frames_req;
	uint32_t frame_samples;
	uint32_t frame_bytes;
	uint32_t frame_ms;
	uint32_t sample_rate_hz;
	bool speech_active;
	bool frame_is_speech;
	bool endpoint_latched;
};

enum vad_event {
	VAD_NO_EVENT = 0,
	VAD_SPEECH_STARTED,
	VAD_ENDPOINT,
};

int vad_init(const struct vad_config *config);

/* Begin a new utterance: clears onset, silence and endpoint-latch state. */
void vad_reset_endpoint(void);

/* As vad_reset_endpoint(), and additionally re-seeds the noise floor. */
void vad_reset_all(void);

/*
 * Process one mono int16 PCM frame. `count` is a sample count, not bytes.
 *
 * endpoint_tracking false : idle. The noise floor adapts, utterance state is
 *                           held clear, and no event is ever returned.
 * endpoint_tracking true  : an utterance is open. Returns VAD_SPEECH_STARTED
 *                           once at onset, then VAD_ENDPOINT once the trailing
 *                           pause is long enough. The endpoint latches so it
 *                           cannot fire twice before vad_reset_endpoint().
 */
enum vad_event vad_process(const int16_t *samples, size_t count,
			   bool endpoint_tracking);

bool vad_speech_active(void);

void vad_get_debug(struct vad_debug *debug);

#endif /* VAD_H */
```

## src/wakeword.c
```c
/*
 * Copyright (c) 2026 Nordic Semiconductor ASA
 *
 * SPDX-License-Identifier: LicenseRef-Nordic-5-Clause
 */

#include <stddef.h>
#include <stdint.h>
#include <string.h>
#include <errno.h>

#include <zephyr/kernel.h>
#include <zephyr/logging/log.h>
#include <nrf_edgeai/nrf_edgeai.h>

#include "wakeword.h"
#include "nrf_edgeai_generated/nrf_edgeai_user_model.h"

LOG_MODULE_REGISTER(ww);

static nrf_edgeai_t *ww_model;
static uint16_t ww_input_samples;
static int16_t ww_input_buffer[512];
static uint16_t ww_input_fill;
static uint32_t ww_count;
static uint32_t ww_history;
static int64_t last_detect_time_ms;
static int64_t suppress_until_ms;

/*
 * The model is not fed while a session is open, so when idle resumes its
 * internal state still holds the audio that triggered the last detection and
 * it re-fires almost immediately. Keep feeding it after a reset so that state
 * flushes, but refuse detections until this much fresh audio has gone in.
 */
#define WW_REFRACTORY_MS 1000

BUILD_ASSERT(CONFIG_WW_HISTORY_SIZE <= 32, "WW_HISTORY_SIZE must fit in uint32_t");

int ww_init(void)
{
    ww_model = nrf_edgeai_user_model();
    __ASSERT_NO_MSG(ww_model);

    nrf_edgeai_err_t err = nrf_edgeai_init(ww_model);
    if (err) {
        LOG_ERR("Model initialization failed (err %d)", err);
        return -ENOENT;
    }

    ww_input_samples = nrf_edgeai_input_window_size(ww_model);
    __ASSERT_NO_MSG(ww_input_samples > 0);
    __ASSERT_NO_MSG(ww_input_samples <= ARRAY_SIZE(ww_input_buffer));

    ww_input_fill = 0U;

    LOG_INF("Wakeword initialized, input_window=%u samples", ww_input_samples);
    return 0;
}

void ww_reset(void)
{
    ww_input_fill = 0U;
    ww_count = 0U;
    ww_history = 0U;
    suppress_until_ms = k_uptime_get() + WW_REFRACTORY_MS;
}

static bool ww_postprocess(void)
{
    const float ww_threshold = CONFIG_WW_PROBABILITY_THRESHOLD / 1000.f;
    const int64_t now_ms = k_uptime_get();
    const int64_t cooldown_ms = 1200;

    const uint16_t predicted_class = ww_model->decoded_output.classif.predicted_class;
    const float class_probability =
        ww_model->decoded_output.classif.probabilities.p_f32[predicted_class];
    const bool ww_frame_positive = class_probability > ww_threshold;

    const bool oldest_entry = (bool)(ww_history & BIT(CONFIG_WW_HISTORY_SIZE - 1));

    if (now_ms < suppress_until_ms) {
        ww_count = 0U;
        ww_history = 0U;
        return false;
    }

    ww_count = ww_count + ww_frame_positive - oldest_entry;
    ww_history = (ww_history << 1) | ww_frame_positive;

    LOG_DBG("postprocess: pred=%u prob=%f count=%u",
        predicted_class, (double)class_probability, ww_count);

    if (ww_count >= CONFIG_WW_COUNT_THRESHOLD) {
        ww_count = 0U;
        ww_history = 0U;

        if ((now_ms - last_detect_time_ms) < cooldown_ms) {
            return false;
        }

        last_detect_time_ms = now_ms;
        return true;
    }

    return false;
}

static int ww_run_window(bool *const ww_detected)
{
    nrf_edgeai_err_t err;

    err = nrf_edgeai_feed_inputs(ww_model, ww_input_buffer, ww_input_samples);
    if (err == NRF_EDGEAI_ERR_INPROGRESS) {
        return -EBUSY;
    } else if (err) {
        LOG_ERR("Failed to feed inputs (err %d)", err);
        return -EPERM;
    }

    err = nrf_edgeai_run_inference(ww_model);
    if (err == NRF_EDGEAI_ERR_INPROGRESS) {
        return -EBUSY;
    } else if (err) {
        LOG_ERR("Failed to run inference (err %d)", err);
        return -EPERM;
    }

    *ww_detected = ww_postprocess();
    return 0;
}

int ww_process(const int16_t *const samples, const uint16_t num_samples, bool *const ww_detected)
{
    uint16_t consumed = 0U;

    __ASSERT_NO_MSG(samples);
    __ASSERT_NO_MSG(ww_detected);

    *ww_detected = false;

    if (ww_model == NULL) {
        return -ENODEV;
    }

    while (consumed < num_samples) {
        const uint16_t space_left = ww_input_samples - ww_input_fill;
        const uint16_t copy_now =
            MIN((uint16_t)(num_samples - consumed), space_left);

        memcpy(&ww_input_buffer[ww_input_fill],
               &samples[consumed],
               copy_now * sizeof(int16_t));

        ww_input_fill += copy_now;
        consumed += copy_now;

        if (ww_input_fill == ww_input_samples) {
            int ret = ww_run_window(ww_detected);
            ww_input_fill = 0U;

            if (ret < 0) {
                return ret;
            }

            if (*ww_detected) {
                return 0;
            }
        }
    }

    return 0;
}
```

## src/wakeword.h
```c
/*
 * Copyright (c) 2026 Nordic Semiconductor ASA
 *
 * SPDX-License-Identifier: LicenseRef-Nordic-5-Clause
 */

#ifndef __WAKEWORD_H__
#define __WAKEWORD_H__

#include <stdbool.h>
#include <stdint.h>

#ifdef __cplusplus
extern "C" {
#endif

int ww_init(void);
void ww_reset(void);
int ww_process(const int16_t *const samples, const uint16_t num_samples, bool *const ww_detected);

#ifdef __cplusplus
}
#endif

#endif /* __WAKEWORD_H__ */
```
